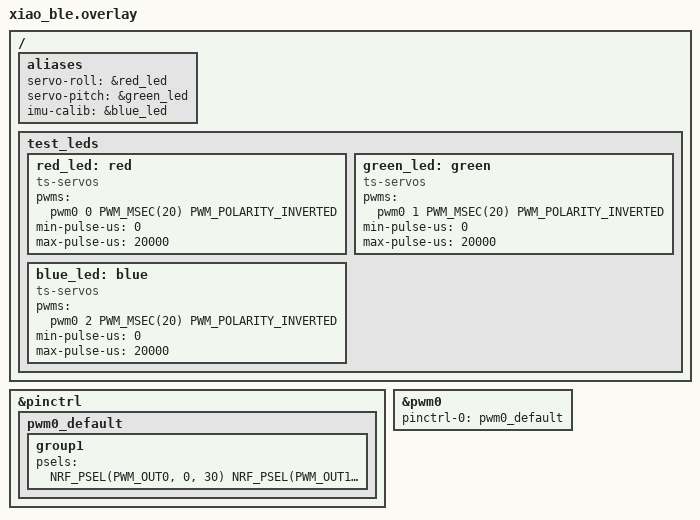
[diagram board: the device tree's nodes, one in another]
&pinctrl {
        pwm0_default: pwm0_default {
                group1 {
                        psels = <NRF_PSEL(PWM_OUT0, 0, 30)   // D9  - Roll servo
                                 NRF_PSEL(PWM_OUT1, 0, 26)   // D10 -Pitch Servo
                                 NRF_PSEL(PWM_OUT2, 0, 06)>; // IMU Calibration
                };
        };
};

&pwm0 {
       status = "okay";
        /delete-property/ pinctrl-1;
       pinctrl-0 = <&pwm0_default>;
       pinctrl-names = "default";
};

/ {
        aliases {
                servo-roll = &red_led;
                servo-pitch = &green_led;
                imu-calib = &blue_led;
        };
        test_leds {
                red_led: red {                            
                        compatible = "ts-servos";
                        pwms = <&pwm0 0 PWM_MSEC(20) PWM_POLARITY_INVERTED>;
                        min-pulse-us = <0>;
                        max-pulse-us = <20000>;
                };
                green_led: green {                            
                        compatible = "ts-servos";
                        pwms = <&pwm0 1 PWM_MSEC(20) PWM_POLARITY_INVERTED>;
                        min-pulse-us = <0>;
                        max-pulse-us = <20000>;
                };
                blue_led: blue {                        
                        compatible = "ts-servos";
                        pwms = <&pwm0 2 PWM_MSEC(20) PWM_POLARITY_INVERTED>;
                        min-pulse-us = <0>;
                        max-pulse-us = <20000>;
                };
        };
};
